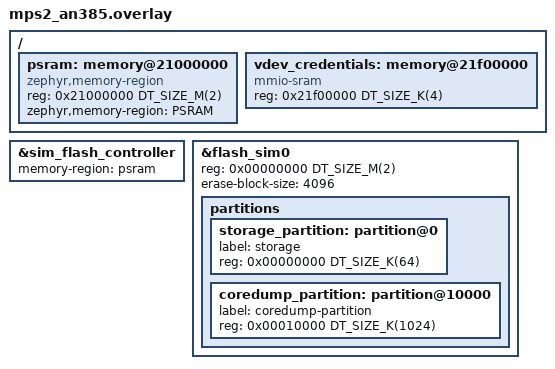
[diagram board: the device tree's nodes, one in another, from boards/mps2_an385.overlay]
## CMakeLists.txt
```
cmake_minimum_required(VERSION 3.20.0)

# The SDK takes the ingest key either from Kconfig or from the application.
# With credentials.conf the key is set at build time, as in the other examples.
# Without it the firmware asks for the key at run time (see src/virtual_device.c).
if (EXISTS "${CMAKE_CURRENT_SOURCE_DIR}/credentials.conf")
    list(APPEND EXTRA_CONF_FILE "${CMAKE_CURRENT_SOURCE_DIR}/credentials.conf")
else()
    list(APPEND EXTRA_CONF_FILE "${CMAKE_CURRENT_SOURCE_DIR}/runtime-credentials.conf")
endif()

find_package(Zephyr REQUIRED HINTS $ENV{ZEPHYR_BASE})
project(zephyr_virtual_device)

add_subdirectory(src/net ${CMAKE_CURRENT_BINARY_DIR}/src/net)

target_sources(app PRIVATE
        src/main.c
        src/sensor_node.c
        src/virtual_device.c
)
```

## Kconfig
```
rsource "src/net/Kconfig"

config VIRTUAL_DEVICE_CRASH_AFTER_SECONDS
	int "Trigger the demo crash automatically this many seconds after the first boot"
	default 0
	help
	  0 disables the automatic crash. The crash can always be triggered by
	  pressing 'c' in the console. A value passed to QEMU at run time in the
	  credentials block (crash_after=<seconds>) takes precedence.

source "Kconfig.zephyr"
```

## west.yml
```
manifest:
  projects:
    # Zephyr RTOS - ARM MPS2+ AN385 (Cortex-M3), emulated by QEMU
    - name: zephyr
      url: https://github.com/zephyrproject-rtos/zephyr
      revision: v4.4.0
      clone-depth: 1
      import:
        path-prefix: external
        name-allowlist:
          - cmsis_6
          - mbedtls
          - zcbor
          - mldsa-native
          - tf-psa-crypto

    # Spotflow Device SDK. CONFIG_SPOTFLOW_INGEST_KEY_DYNAMIC, which the
    # prebuilt Docker image needs, is on main since commit 0349981.
    - name: spotflow-device-sdk
      url: https://github.com/spotflow-io/device-sdk
      revision: main
      path: external/modules/lib/spotflow
```

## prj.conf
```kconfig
# Spotflow SDK
CONFIG_SPOTFLOW=y
CONFIG_SPOTFLOW_MODULE_DEFAULT_LOG_LEVEL=3

# Logging
CONFIG_LOG=y
CONFIG_LOG_BUFFER_SIZE=2048
CONFIG_LOG_RUNTIME_FILTERING=y
CONFIG_REQUIRES_FLOAT_PRINTF=y
CONFIG_LOG_FUNC_NAME_PREFIX_INF=y
CONFIG_LOG_FUNC_NAME_PREFIX_WRN=y
CONFIG_LOG_FUNC_NAME_PREFIX_ERR=y
CONFIG_SPOTFLOW_LOG_BACKEND_QUEUE_SIZE=16
CONFIG_SPOTFLOW_LOG_BUFFER_SIZE=256
CONFIG_SPOTFLOW_CBOR_LOG_MAX_LEN=512
CONFIG_HEAP_MEM_POOL_ADD_SIZE_SPOTFLOW_LOGGING=3072

# Metrics
CONFIG_SPOTFLOW_METRICS=y
CONFIG_SPOTFLOW_METRICS_SYSTEM=y
CONFIG_SPOTFLOW_METRICS_HEARTBEAT=y
CONFIG_SPOTFLOW_METRICS_HEARTBEAT_INTERVAL=60
# Keep the SDK's metric registration messages out of your log view
CONFIG_SPOTFLOW_METRICS_PROCESSING_LOG_LEVEL=2

# Coredumps
CONFIG_SPOTFLOW_COREDUMPS=y
CONFIG_DEBUG_COREDUMP_MEMORY_DUMP_LINKER_RAM=y
CONFIG_DEBUG_COREDUMP_THREADS_METADATA=y

# Networking
CONFIG_NETWORKING=y
CONFIG_NET_MGMT=y
CONFIG_NET_MGMT_EVENT=y
CONFIG_NET_MGMT_EVENT_INFO=y
CONFIG_NET_CONFIG_AUTO_INIT=n
CONFIG_NET_CONNECTION_MANAGER=y
CONFIG_NET_DHCPV4=y
CONFIG_NET_IPV4=y
CONFIG_NET_IPV6=n
CONFIG_NET_TCP=y
CONFIG_NET_UDP=y

# Flash / Settings (required by Spotflow for state persistence)
CONFIG_FLASH=y
CONFIG_FLASH_MAP=y
CONFIG_NVS=y
CONFIG_SETTINGS=y
CONFIG_SETTINGS_NVS=y

# Stack / Heap
CONFIG_MAIN_STACK_SIZE=4096
CONFIG_HEAP_MEM_POOL_ADD_SIZE_SPOTFLOW_METRICS=6144
```

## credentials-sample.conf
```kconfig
# Copy this file to credentials.conf and fill in your values.
# credentials.conf is excluded from version control by .gitignore.
#
# Only needed when you build the firmware yourself. The prebuilt image takes
# the same values at run time (see README.md).
CONFIG_SPOTFLOW_DEVICE_ID="zephyr-virtual-device-001"
CONFIG_SPOTFLOW_INGEST_KEY=""
```

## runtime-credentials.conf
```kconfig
# Used when credentials.conf does not exist (see CMakeLists.txt), for example in
# the Docker image. The firmware then gets the ingest key at run time from
# spotflow_on_ingest_key_requested() in src/virtual_device.c.
CONFIG_SPOTFLOW_INGEST_KEY_DYNAMIC=y
```

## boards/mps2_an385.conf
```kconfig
# The emulated clock must follow wall-clock time, because the device talks to
# a real server. With icount enabled, QEMU fast-forwards idle time and network
# timeouts fire early.
CONFIG_QEMU_ICOUNT=n

# QEMU user-mode networking (SLIRP): outbound TCP through the host, no root
# and no TAP interface needed. The emulated NIC is the board's LAN9118.
CONFIG_NET_QEMU_USER=y

# Zephyr's DHCP client waits a random 1-10 s before its first request, so
# that many devices booting at once do not flood a real network's DHCP
# server. QEMU's built-in server serves only this device, so wait the
# minimum (1 s) and connect to Spotflow sooner.
CONFIG_NET_DHCPV4_INITIAL_DELAY_MAX=2

# The MPS2 AN385 model has no entropy source. This generator is NOT
# cryptographically secure. It is acceptable for a demo device that holds no
# secrets other than a free-tier ingest key. Never use it in a product.
CONFIG_TEST_RANDOM_GENERATOR=y

# The Ethernet driver RX thread and TLS need more room than the defaults
CONFIG_NET_PKT_RX_COUNT=32
CONFIG_NET_PKT_TX_COUNT=32
CONFIG_NET_BUF_RX_COUNT=64
CONFIG_NET_BUF_TX_COUNT=64
```

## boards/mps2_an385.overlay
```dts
/*
 * QEMU's mps2-an385 machine has 16 MiB of PSRAM at 0x21000000 that Zephyr's
 * board definition does not use. This overlay puts two things there:
 *
 *   0x21000000  2 MiB   the board's simulated flash, moved out of .bss so
 *                       that it keeps its content across a reset
 *   0x21f00000  4 KiB   run-time credentials block, written by QEMU's
 *                       generic loader (-device loader,file=...,addr=0x21f00000)
 *
 * Simulated flash layout after this overlay:
 *   storage_partition   0x00000000   64 KiB   (NVS / settings)
 *   coredump_partition  0x00010000    1 MiB   (Zephyr coredump backend)
 *
 * RAM content survives a warm reset in QEMU, so a core dump written before
 * the reboot is still there when the firmware starts again. It does not
 * survive a QEMU restart.
 */

#include <mem.h>

/ {
	psram: memory@21000000 {
		compatible = "zephyr,memory-region", "mmio-sram";
		reg = <0x21000000 DT_SIZE_M(2)>;
		zephyr,memory-region = "PSRAM";
	};

	vdev_credentials: memory@21f00000 {
		compatible = "mmio-sram";
		reg = <0x21f00000 DT_SIZE_K(4)>;
	};
};

/delete-node/ &storage_partition;

&sim_flash_controller {
	/* With a memory region, the simulator does not erase the flash at boot */
	memory-region = <&psram>;
};

&flash_sim0 {
	reg = <0x00000000 DT_SIZE_M(2)>;
	erase-block-size = <4096>;

	partitions {
		storage_partition: partition@0 {
			label = "storage";
			reg = <0x00000000 DT_SIZE_K(64)>;
		};

		coredump_partition: partition@10000 {
			label = "coredump-partition";
			reg = <0x00010000 DT_SIZE_K(1024)>;
		};
	};
};
```

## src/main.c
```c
#include <zephyr/kernel.h>
#include <zephyr/logging/log.h>

#include "net.h"
#include "sensor_node.h"
#include "virtual_device.h"

LOG_MODULE_REGISTER(main, LOG_LEVEL_INF);

#define SENSOR_PERIOD_SECONDS 2

int main(void)
{
	LOG_INF("Zephyr virtual device example starting");
	LOG_INF("This is real Zephyr firmware with the Spotflow SDK, running on an emulated Cortex-M3.");

	virtual_device_init();

	/* Allow the network interface driver to finish initialization. */
	k_sleep(K_SECONDS(1));
	spotflow_sample_net_init();

	int rc = sensor_node_init();
	if (rc < 0) {
		LOG_ERR("Failed to initialize sensor node: %d", rc);
		return rc;
	}

	int crash_after = virtual_device_crash_after_seconds();
	bool auto_crash_pending = virtual_device_is_first_boot() && crash_after > 0;

	if (auto_crash_pending) {
		LOG_INF("The demo crash will fire automatically in %d seconds", crash_after);
	} else if (!virtual_device_is_first_boot()) {
		LOG_INF("Device restarted after a reset. A stored core dump is uploaded now.");
	}

	while (true) {
		bool crash_now = virtual_device_crash_requested();

		if (crash_now) {
			LOG_WRN("Key 'c' received. Arming reproducible crash path.");
		}

		if (auto_crash_pending && k_uptime_get() >= (int64_t)crash_after * MSEC_PER_SEC) {
			LOG_WRN("Auto-crash timer expired. Arming reproducible crash path.");
			auto_crash_pending = false;
			crash_now = true;
		}

		if (crash_now) {
			sensor_node_trigger_repro_crash();
		}

		sensor_node_step();
		k_sleep(K_SECONDS(SENSOR_PERIOD_SECONDS));
	}

	return 0;
}
```

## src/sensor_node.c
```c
#include "sensor_node.h"

#include <zephyr/kernel.h>
#include <zephyr/logging/log.h>
#include <zephyr/random/random.h>

#include "metrics/spotflow_metrics_backend.h"

LOG_MODULE_REGISTER(sensor_node, LOG_LEVEL_INF);

/* ---- application metrics ---- */
static struct spotflow_metric_float *g_temperature_metric;
static struct spotflow_metric_int   *g_read_errors_metric;

/* ---- crash path state ---- */

/*
 * Alert callback type.  In a real product this would be set during
 * initialization based on the device configuration (e.g. loaded from NVS or
 * provisioned from the cloud).  On this device variant the callback was never
 * registered because the node was provisioned as a sensor-only unit not wired
 * into an alerting backend.
 *
 * The firmware calls the callback unconditionally whenever the threshold is
 * exceeded: a classic null-function-pointer bug.
 */
typedef void (*alert_fn_t)(float temp_celsius);

static alert_fn_t g_alert_callback = NULL; /* not configured on this device */
static float      g_temp_threshold  = 40.0f; /* degrees C, safe under normal conditions */
static bool       g_repro_mode      = false;
static int        g_loop_count      = 0;

/* ---- helpers ---- */

static float rand_range(float min, float max)
{
	return min + ((float)(sys_rand32_get() % 1000) / 1000.0f) * (max - min);
}

/*
 * check_threshold: called every sensor cycle when repro mode is armed.
 *
 * BUG: g_alert_callback is NULL (alert handler not registered on this
 * device).  This models a real pattern: a callback is registered only on
 * certain device variants during initialization, but the processing path
 * calls it unconditionally, without a null check.
 */
static void check_threshold(float temp_celsius)
{
	if (temp_celsius > g_temp_threshold) {
		LOG_WRN("Temperature threshold exceeded: %.1f C (threshold: %.1f C)",
			(double)temp_celsius, (double)g_temp_threshold);
		/* NULL dereference: fatal fault on next line */
		g_alert_callback(temp_celsius);
	}
}

/* ---- public API ---- */

int sensor_node_init(void)
{
	int rc;

	g_loop_count = 0;
	g_repro_mode = false;

	rc = spotflow_register_metric_float(
		"temperature_celsius",
		SPOTFLOW_AGG_INTERVAL_NONE,
		&g_temperature_metric);
	if (rc < 0) {
		LOG_ERR("Failed to register temperature_celsius metric: %d", rc);
		return rc;
	}

	rc = spotflow_register_metric_int(
		"read_errors",
		SPOTFLOW_AGG_INTERVAL_NONE,
		&g_read_errors_metric);
	if (rc < 0) {
		LOG_ERR("Failed to register read_errors metric: %d", rc);
		return rc;
	}

	LOG_INF("Sensor node ready. Press 'c' in the console to reproduce the crash.");
	return 0;
}

void sensor_node_step(void)
{
	++g_loop_count;

	/* Simulate temperature in 28–34 °C range */
	float temp = rand_range(28.0f, 34.0f);

	int rc = spotflow_report_metric_float(g_temperature_metric, temp);
	if (rc < 0) {
		LOG_ERR("Failed to report temperature_celsius: %d", rc);
	}

	LOG_INF("Sensor reading: %.1f C", (double)temp);

	/* Simulate occasional I2C read errors (every 9th loop) */
	if ((g_loop_count % 9) == 0) {
		LOG_WRN("Sensor I2C read timeout, retrying");
		rc = spotflow_report_event(g_read_errors_metric);
		if (rc < 0) {
			LOG_ERR("Failed to report read_errors: %d", rc);
		}
	}

	/* Crash path: armed from the console or by the auto-crash timer */
	if (g_repro_mode && g_loop_count >= 3) {
		check_threshold(temp);
	}
}

void sensor_node_trigger_repro_crash(void)
{
	LOG_WRN("Crash path armed. Lowering temperature threshold to 20.0 C.");
	g_repro_mode     = true;
	g_loop_count     = 0;
	g_temp_threshold = 20.0f; /* below normal range, will trigger on next cycle */
}
```

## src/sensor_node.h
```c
#ifndef ZEPHYR_VIRTUAL_DEVICE_SENSOR_NODE_H
#define ZEPHYR_VIRTUAL_DEVICE_SENSOR_NODE_H

int  sensor_node_init(void);
void sensor_node_step(void);
void sensor_node_trigger_repro_crash(void);

#endif /* ZEPHYR_VIRTUAL_DEVICE_SENSOR_NODE_H */
```

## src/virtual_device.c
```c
/*
 * Everything that exists only because this device is emulated:
 *
 *  - Run-time credentials. A prebuilt firmware image cannot contain your
 *    ingest key, so QEMU places a small text block in memory before the CPU
 *    starts (-device loader,file=credentials.bin,addr=0x21f00000). The
 *    firmware hands the device ID to the Spotflow SDK through
 *    spotflow_override_device_id() and the ingest key through
 *    spotflow_on_ingest_key_requested().
 *
 *    The SDK takes the ingest key either from Kconfig or from the application,
 *    never both. A build without credentials.conf enables
 *    CONFIG_SPOTFLOW_INGEST_KEY_DYNAMIC (see runtime-credentials.conf) and
 *    needs the block. A build with credentials.conf uses the key from Kconfig.
 *
 *  - A console key instead of a user button.
 *
 *  - A boot counter kept in RAM that survives QEMU's warm reset, so the
 *    automatic demo crash fires once and not in a loop.
 */

#include "virtual_device.h"

#include <stdlib.h>
#include <string.h>

#include <zephyr/device.h>
#include <zephyr/devicetree.h>
#include <zephyr/drivers/uart.h>
#include <zephyr/kernel.h>
#include <zephyr/logging/log.h>

#ifdef CONFIG_SPOTFLOW_INGEST_KEY_DYNAMIC
#include <spotflow/ingest_key.h>
#endif

LOG_MODULE_REGISTER(virtual_device, LOG_LEVEL_INF);

#define CREDENTIALS_NODE DT_NODELABEL(vdev_credentials)
#define CREDENTIALS_ADDR ((const char *)DT_REG_ADDR(CREDENTIALS_NODE))
#define CREDENTIALS_SIZE DT_REG_SIZE(CREDENTIALS_NODE)
#define CREDENTIALS_MAGIC "SFVDEV1\n"

#define BOOT_MARKER 0x5f0b0075U

static char g_device_id[65];
static char g_ingest_key[257];
static int g_crash_after_seconds = CONFIG_VIRTUAL_DEVICE_CRASH_AFTER_SECONDS;

/* Not zeroed by Zephyr at start-up and not cleared by QEMU on a warm reset. */
static __noinit uint32_t g_boot_marker;
static __noinit uint32_t g_boot_count;
static bool g_first_boot;

static const struct device *const g_console = DEVICE_DT_GET(DT_CHOSEN(zephyr_console));

/* Copies the value of "key=value\n" from the block into out. */
static void read_value(const char *block, size_t block_len, const char *key, char *out,
		       size_t out_size)
{
	size_t key_len = strlen(key);
	const char *line = block;
	const char *end = block + block_len;

	while (line < end) {
		const char *eol = memchr(line, '\n', end - line);

		if (eol == NULL) {
			eol = end;
		}

		if ((size_t)(eol - line) > key_len && memcmp(line, key, key_len) == 0 &&
		    line[key_len] == '=') {
			size_t value_len = eol - line - key_len - 1;

			if (value_len >= out_size) {
				LOG_ERR("Value of '%s' is too long (%u characters)", key,
					(unsigned int)value_len);
				return;
			}
			memcpy(out, line + key_len + 1, value_len);
			out[value_len] = '\0';
			return;
		}
		line = eol + 1;
	}
}

static void read_credentials_block(void)
{
	const char *block = CREDENTIALS_ADDR;

	if (memcmp(block, CREDENTIALS_MAGIC, strlen(CREDENTIALS_MAGIC)) != 0) {
		LOG_INF("No run-time credentials block");
		return;
	}

	size_t block_len = strnlen(block, CREDENTIALS_SIZE);
	char crash_after[12] = "";

	read_value(block, block_len, "device_id", g_device_id, sizeof(g_device_id));
	read_value(block, block_len, "ingest_key", g_ingest_key, sizeof(g_ingest_key));
	read_value(block, block_len, "crash_after", crash_after, sizeof(crash_after));

	if (crash_after[0] != '\0') {
		g_crash_after_seconds = atoi(crash_after);
	}

	LOG_INF("Run-time credentials loaded (device ID: %s, ingest key: %s)",
		g_device_id[0] != '\0' ? g_device_id : "<from Kconfig>",
		g_ingest_key[0] != '\0' ? "provided" : "not provided");
}

void virtual_device_init(void)
{
	if (g_boot_marker != BOOT_MARKER) {
		g_boot_marker = BOOT_MARKER;
		g_boot_count = 0;
	}
	g_first_boot = (g_boot_count == 0);
	g_boot_count++;

	read_credentials_block();

#ifdef CONFIG_SPOTFLOW_INGEST_KEY_DYNAMIC
	if (g_ingest_key[0] == '\0') {
		LOG_ERR("No ingest key. Start the device with run-virtual-device.sh, or set "
			"CONFIG_SPOTFLOW_INGEST_KEY in credentials.conf and rebuild.");
	}
#else
	if (g_ingest_key[0] != '\0') {
		LOG_WRN("This firmware was built with the ingest key from credentials.conf. "
			"The key passed at run time is ignored.");
	}
#endif
}

bool virtual_device_is_first_boot(void)
{
	return g_first_boot;
}

int virtual_device_crash_after_seconds(void)
{
	return g_crash_after_seconds;
}

bool virtual_device_crash_requested(void)
{
	unsigned char c;
	bool requested = false;

	if (!device_is_ready(g_console)) {
		return false;
	}

	while (uart_poll_in(g_console, &c) == 0) {
		if (c == 'c' || c == 'C') {
			requested = true;
		}
	}

	return requested;
}

/* Spotflow SDK callbacks */

/* Returning NULL keeps CONFIG_SPOTFLOW_DEVICE_ID. */
const char *spotflow_override_device_id(void)
{
	return g_device_id[0] != '\0' ? g_device_id : NULL;
}

#ifdef CONFIG_SPOTFLOW_INGEST_KEY_DYNAMIC
/* Returning NULL makes the SDK skip this connection attempt and ask again later. */
const char *spotflow_on_ingest_key_requested(void)
{
	return g_ingest_key[0] != '\0' ? g_ingest_key : NULL;
}
#endif
```

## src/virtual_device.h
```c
#ifndef ZEPHYR_VIRTUAL_DEVICE_VIRTUAL_DEVICE_H
#define ZEPHYR_VIRTUAL_DEVICE_VIRTUAL_DEVICE_H

#include <stdbool.h>

/* Parses the run-time credentials block. Call once, before the network starts. */
void virtual_device_init(void);

/* True on the first boot of this QEMU run, false after a warm reset. */
bool virtual_device_is_first_boot(void);

/* Seconds after the first boot at which the demo crash fires, 0 if disabled. */
int virtual_device_crash_after_seconds(void);

/* True once the user pressed 'c' in the console. */
bool virtual_device_crash_requested(void);

#endif /* ZEPHYR_VIRTUAL_DEVICE_VIRTUAL_DEVICE_H */
```
